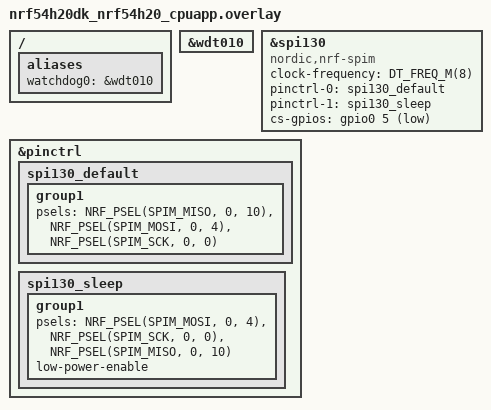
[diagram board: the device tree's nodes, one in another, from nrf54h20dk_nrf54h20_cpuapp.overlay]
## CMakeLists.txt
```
# Copyright (c) 2024 Nordic Semiconductor ASA
# SPDX-License-Identifier: Apache-2.0

cmake_minimum_required(VERSION 3.20.0)
find_package(Zephyr REQUIRED HINTS $ENV{ZEPHYR_BASE})

project(test_power_management)

target_include_directories(app PRIVATE src)

target_sources(app PRIVATE
  src/main.c
  src/watchdog.c
)
```

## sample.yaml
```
sample:
  name: Hello World for multiple board targets using Sysbuild
  description: |
    Hello World application that builds for multiple targets. Both images print
    the board target they were run on.

common:
  sysbuild: true
  harness: console
  harness_config:
    type: multi_line
    regex:
      - "Hello world from .*"

tests:
  sample.sysbuild.hello_world.nrf5340dk_cpuapp_cpunet:
    platform_allow:
      - nrf5340dk/nrf5340/cpuapp
    integration_platforms:
      - nrf5340dk/nrf5340/cpuapp
    extra_args:
      SB_CONF_FILE=sysbuild/nrf5340dk_nrf5340_cpunet.conf

  sample.sysbuild.test_power_management.nrf54h20dk_cpuapp_cpurad:
    platform_allow:
      - nrf54h20dk/nrf54h20/cpuapp
    integration_platforms:
      - nrf54h20dk/nrf54h20/cpuapp
    extra_args:
      SB_CONF_FILE=sysbuild/nrf54h20dk_nrf54h20_cpurad.conf

  sample.sysbuild.hello_world.nrf54h20dk_cpuapp_cpuppr:
    platform_allow:
      - nrf54h20dk/nrf54h20/cpuapp
    integration_platforms:
      - nrf54h20dk/nrf54h20/cpuapp
    extra_args:
      SB_CONF_FILE=sysbuild/nrf54h20dk_nrf54h20_cpuppr.conf
      hello_world_SNIPPET=nordic-ppr

  sample.sysbuild.hello_world.nrf54h20dk_cpuapp_cpuppr_xip:
    platform_allow:
      - nrf54h20dk/nrf54h20/cpuapp
    integration_platforms:
      - nrf54h20dk/nrf54h20/cpuapp
    extra_args:
      SB_CONF_FILE=sysbuild/nrf54h20dk_nrf54h20_cpuppr_xip.conf
      hello_world_SNIPPET=nordic-ppr-xip

  sample.sysbuild.hello_world.nrf54l15dk_nrf54l15_cpuflpr:
    platform_allow:
      - nrf54l15dk/nrf54l15/cpuapp
    integration_platforms:
      - nrf54l15dk/nrf54l15/cpuapp
    extra_args:
      SB_CONF_FILE=sysbuild/nrf54l15dk_nrf54l15_cpuflpr.conf
      hello_world_SNIPPET=nordic-flpr

  sample.sysbuild.hello_world.nrf54h20dk_cpuapp_cpuflpr:
    platform_allow:
      - nrf54h20dk/nrf54h20/cpuapp
    integration_platforms:
      - nrf54h20dk/nrf54h20/cpuapp
    extra_args:
      SB_CONF_FILE=sysbuild/nrf54h20dk_nrf54h20_cpuflpr.conf
      hello_world_SNIPPET=nordic-flpr

  sample.sysbuild.hello_world.nrf54h20dk_cpuapp_cpuflpr_xip:
    platform_allow:
      - nrf54h20dk/nrf54h20/cpuapp
    integration_platforms:
      - nrf54h20dk/nrf54h20/cpuapp
    extra_args:
      SB_CONF_FILE=sysbuild/nrf54h20dk_nrf54h20_cpuflpr_xip.conf
      hello_world_SNIPPET=nordic-flpr-xip
```

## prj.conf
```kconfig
CONFIG_PM=y
CONFIG_PM_DEVICE=y

# Watchdog timer
CONFIG_WATCHDOG=y
CONFIG_TASK_WDT=y
CONFIG_TASK_WDT_HW_FALLBACK=y
CONFIG_TASK_WDT_MIN_TIMEOUT=5000
CONFIG_TASK_WDT_HW_FALLBACK_DELAY=100

CONFIG_GPIO=y

# Shell and dependencies
CONFIG_THREAD_MONITOR=y
CONFIG_THREAD_NAME=y
CONFIG_SHELL=y
CONFIG_SHELL_THREAD_PRIORITY_OVERRIDE=y
CONFIG_SHELL_THREAD_PRIORITY=10
CONFIG_LOG=y
CONFIG_LOG_PROCESS_TRIGGER_THRESHOLD=1
CONFIG_LOG_SPEED=y
CONFIG_LOG_PRINTK=y
CONFIG_LOG_BUFFER_SIZE=4096
CONFIG_LOG_PROCESS_THREAD_CUSTOM_PRIORITY=y
CONFIG_LOG_PROCESS_THREAD_PRIORITY=10

# Threads statistics
CONFIG_THREAD_RUNTIME_STATS=y
CONFIG_SCHED_THREAD_USAGE_ANALYSIS=y

# Test SPI interface for GPIO reuse with interrupts
CONFIG_SPI=y
```

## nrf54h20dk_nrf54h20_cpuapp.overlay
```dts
&wdt010 {
	status = "okay";
};

&spi130 {
	compatible = "nordic,nrf-spim";
	status = "okay";
	clock-frequency = <DT_FREQ_M(8)>;
	pinctrl-0 = <&spi130_default>;
	pinctrl-1 = <&spi130_sleep>;
	pinctrl-names = "default", "sleep";

	cs-gpios = <&gpio0 5 GPIO_ACTIVE_LOW>;
};

&pinctrl {
	spi130_default: spi130_default {
		group1 {
			psels = <NRF_PSEL(SPIM_MISO, 0, 10)>,
				<NRF_PSEL(SPIM_MOSI, 0, 4)>,
				<NRF_PSEL(SPIM_SCK, 0, 0)>;
		};
	};

	spi130_sleep: spi130_sleep {
		group1 {
			psels = <NRF_PSEL(SPIM_MOSI, 0, 4)>,
				<NRF_PSEL(SPIM_SCK, 0, 0)>,
				<NRF_PSEL(SPIM_MISO, 0, 10)>;
			low-power-enable;
		};
		/*group2 {
			psels = <NRF_PSEL_DISCONNECTED(SPIM_MISO)>;
		};*/
	};
};

/ {
	aliases {
		watchdog0 = &wdt010;
	};
};
```

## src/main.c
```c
#include <zephyr/drivers/gpio.h>
#include <zephyr/ipc/ipc_service.h>
#include <zephyr/kernel.h>
#include <zephyr/pm/policy.h>
#include <zephyr/pm/pm.h>
#include <zephyr/sys/printk.h>

#include "watchdog.h"

#define MAX_SUSPENDABLE_THREADS_COUNT 10

static void resume_system(void);

static const struct gpio_dt_spec app_led = GPIO_DT_SPEC_GET(DT_NODELABEL(led0), gpios);
static const struct gpio_dt_spec app_button_suspend = GPIO_DT_SPEC_GET(DT_NODELABEL(button0), gpios);
static const struct gpio_dt_spec app_button_resume = GPIO_DT_SPEC_GET(DT_NODELABEL(button2), gpios);

static struct gpio_callback suspend_app_button_callback_data;
static struct gpio_callback resume_app_button_callback_data;

static bool is_suspended = false;

static size_t suspendable_threads_count;
static k_tid_t suspendable_thread_ids[MAX_SUSPENDABLE_THREADS_COUNT];

static void ipc_endpoint_bound_callback(void *priv)
{
	printk("IPC endpoint successfully bound\n.");
}

static void ipc_endpoint_received_callback(const void *data, size_t len, void *priv)
{
	printk("Received an IPC message\n.");

	if (is_suspended)
		resume_system();
}

static struct ipc_ept_cfg ipc_endpoint_config =
{
	.name = "ept1",
	.cb =
	{
		.bound = ipc_endpoint_bound_callback,
		.received = ipc_endpoint_received_callback
	}
};
static struct ipc_ept ipc_endpoint;
static const struct device *ipc_instance = DEVICE_DT_GET(DT_NODELABEL(ipc0));

static void __attribute__((unused)) burn_cpu(void)
{
	volatile int a = 0, i;

	for (i = 0; i < 50000000; i++)
	{
		a += 1239;
		a *= -7;
		a /= 11;
	}
}

static void thread_background_entry(void *p1, void *p2, void *p3)
{
	unsigned int i = 0;
	int channel;

	ARG_UNUSED(p1);
	ARG_UNUSED(p2);
	ARG_UNUSED(p3);

	channel = task_wdt_add(2000, watchdog_callback, "background");
	if (channel < 0)
	{
		printk("Failed to initialize the watchdog for background thread; err=%d", -channel);
		return;
	}

	printk("Background thread is ready.\n");

	while (1)
	{
		printk("BACKGROUND %u\n", i);
		i++;

		task_wdt_feed(channel);
		k_msleep(1000);
	}
}
// Higher priority thread to be able to interrupt the busy waits in the main thread
K_THREAD_DEFINE(thread_background, 512, thread_background_entry, NULL, NULL, NULL, -1, K_ESSENTIAL, 1);

static void cache_suspendable_thread_callback(const struct k_thread *thread, void *user_data)
{
	k_tid_t thread_id;
	const char *name;
	bool keep_thread = false;

	ARG_UNUSED(user_data);

	// Retrieve the current thread name
	thread_id = (k_tid_t) thread;
	name = k_thread_name_get(thread_id);

	// Do not try to identify the thread if it has no name
	if (name == NULL)
		return;

	// The shell thread is always ready and keeps waking the system, so it needs to be suspended
	if (strcmp(name, "main") == 0)
		keep_thread = true;
	else if (strcmp(name, "shell_uart") == 0)
		keep_thread = true;
	else if (strcmp(name, "logging") == 0)
		keep_thread = true;
	else if (strcmp(name, "thread_background") == 0)
		keep_thread = true;

	if (keep_thread)
	{
		if (suspendable_threads_count >= MAX_SUSPENDABLE_THREADS_COUNT)
		{
			printk("No more room in the suspendable threads array.");
			k_sleep(K_FOREVER);
		}
		suspendable_thread_ids[suspendable_threads_count] = thread_id;
		suspendable_threads_count++;
		printk("Added the thread named \"%s\" to the suspendable list.\n", name);
	}
}

static void cache_suspendable_threads()
{
    suspendable_threads_count = 0;

    k_thread_foreach(cache_suspendable_thread_callback, NULL);

    printk("Cached %zu suspendable threads.\n", suspendable_threads_count);
}

static void suspend_threads()
{
	const char *name;
	k_tid_t thread_id;

	for (size_t i = 0; i < suspendable_threads_count; i++)
	{
		thread_id = suspendable_thread_ids[i];
		k_thread_suspend(thread_id);

		name = k_thread_name_get(thread_id);
		printk("Suspending thread named \"%s\".\n", name);
	}
}

static void resume_threads()
{
	const char *name;
	k_tid_t thread_id;

	for (size_t i = 0; i < suspendable_threads_count; i++)
	{
		thread_id = suspendable_thread_ids[i];
		k_thread_resume(thread_id);

		name = k_thread_name_get(thread_id);
		printk("Resuming thread named \"%s\".\n", name);
	}
}

static void gpio_callback(const struct device *port, struct gpio_callback *cb, gpio_port_pins_t pins)
{
	ARG_UNUSED(port);
	ARG_UNUSED(cb);
	ARG_UNUSED(pins);

	printk("\033[35mGPIO interrupt callback.\033[0m\n");

	if (!is_suspended && (pins & (1 << 8)))
	{
		printk("\033[35mSUSPEND\033[0m\n");
		pm_policy_state_lock_put(PM_STATE_SUSPEND_TO_IDLE, PM_ALL_SUBSTATES); // Allow reaching suspend to idle
		task_wdt_suspend();
		suspend_threads();
		is_suspended = true;
	}
	else if (is_suspended && (pins & (1 << 10)))
	{
		printk("\033[35mRESUME\033[0m\n");
		resume_system();

		// Tell the radio core to wake up (the message content is ignored for now)
		ipc_service_send(&ipc_endpoint, "wake", 5);
	}
}

static void resume_system(void)
{
	task_wdt_resume();
	resume_threads();
	pm_policy_state_lock_get(PM_STATE_SUSPEND_TO_IDLE, PM_ALL_SUBSTATES); // Stay in active mode
	is_suspended = false;
}

void power_notifier_entry(enum pm_state state)
{
	if (state == PM_STATE_SUSPEND_TO_IDLE)
	{
		// Tell that the App core is in suspend to idle mode
		gpio_pin_set_dt(&app_led, 1);
	}
}

void power_notifier_exit(enum pm_state state)
{
	if (state == PM_STATE_SUSPEND_TO_IDLE)
	{
		// Tell that the App core exited the suspend to idle mode
		gpio_pin_set_dt(&app_led, 0);
	}
}

static struct pm_notifier power_notifier =
{
	.state_entry = power_notifier_entry,
	.state_exit = power_notifier_exit
};

int main(void)
{
	int states_count, ret, channel;
	const struct pm_state_info *states;
	unsigned int i = 0;
	uint32_t start_time = 0, current_time;

	/* Set the main thread priority less than the shell and logging threads,
	 * so they continue working while the main thread is using 100% of the remaining resources.
	 */
	k_thread_priority_set(k_current_get(), 12);

	// Force staying in active mode by locking all other states
	pm_policy_state_lock_get(PM_STATE_RUNTIME_IDLE, PM_ALL_SUBSTATES);
	pm_policy_state_lock_get(PM_STATE_SUSPEND_TO_IDLE, PM_ALL_SUBSTATES);
	pm_policy_state_lock_get(PM_STATE_STANDBY, PM_ALL_SUBSTATES);
	pm_policy_state_lock_get(PM_STATE_SUSPEND_TO_RAM, PM_ALL_SUBSTATES);
	pm_policy_state_lock_get(PM_STATE_SUSPEND_TO_DISK, PM_ALL_SUBSTATES);

	cache_suspendable_threads();

	// Callbacks called when the power mode changes
	pm_notifier_register(&power_notifier);

	ret = watchdog_init();
	if (ret < 0)
		return -1;

	printk("Hello world from %s\n", CONFIG_BOARD_TARGET);

	// Retrieving power states
	states_count = pm_state_cpu_get_all(0, &states);
	printk("Power states count : %d.\n", states_count);

	if (!gpio_is_ready_dt(&app_led))
	{
		printk("App LED GPIO is not ready.\n");
		return -1;
	}
	if (!gpio_is_ready_dt(&app_button_resume))
	{
		printk("Suspend App button GPIO is not ready.\n");
		return -1;
	}
	if (!gpio_is_ready_dt(&app_button_suspend))
	{
		printk("Resume App button GPIO is not ready.\n");
		return -1;
	}

	ret = gpio_pin_configure_dt(&app_led, GPIO_OUTPUT_ACTIVE);
	if (ret < 0)
	{
		printk("Failed to configure the App LED GPIO (%d).\n", ret);
		return -1;
	}
	ret = gpio_pin_configure_dt(&app_button_resume, GPIO_INPUT | GPIO_PULL_UP);
	if (ret < 0)
	{
		printk("Failed to configure the suspend App button GPIO (%d).\n", ret);
		return -1;
	}
	ret = gpio_pin_configure_dt(&app_button_suspend, GPIO_INPUT | GPIO_PULL_UP);
	if (ret < 0)
	{
		printk("Failed to configure the resume App button GPIO (%d).\n", ret);
		return -1;
	}

	ret = gpio_pin_interrupt_configure_dt(&app_button_suspend, GPIO_INT_EDGE_FALLING);
	if (ret < 0)
	{
		printk("Failed to configure the suspend App button interrupt (%d).\n", ret);
		return -1;
	}
	ret = gpio_pin_interrupt_configure_dt(&app_button_resume, GPIO_INT_EDGE_FALLING);
	if (ret < 0)
	{
		printk("Failed to configure the resume App button interrupt (%d).\n", ret);
		return -1;
	}

	gpio_init_callback(&suspend_app_button_callback_data, gpio_callback, BIT(app_button_suspend.pin));
	if (gpio_add_callback_dt(&app_button_suspend, &suspend_app_button_callback_data) < 0)
	{
		printk("Failed to add a callback to the suspend App button GPIO.\n");
		return -1;
	}
	gpio_init_callback(&resume_app_button_callback_data, gpio_callback, BIT(app_button_resume.pin));
	if (gpio_add_callback_dt(&app_button_resume, &resume_app_button_callback_data) < 0)
	{
		printk("Failed to add a callback to the resume App button GPIO.\n");
		return -1;
	}

	ret = ipc_service_open_instance(ipc_instance);
	if ((ret != 0) && (ret != -EALREADY))
	{
		printk("Failed to open the inter processor service instance (%d).", ret);
		return ret;
	}

	ret = ipc_service_register_endpoint(ipc_instance, &ipc_endpoint, &ipc_endpoint_config);
	if (ret != 0)
	{
		printk("Failed to register the inter processor service endpoint (%d).", ret);
		return ret;
	}

	// Turn the power mode LED off to tell that the board is in active mode
	gpio_pin_set_dt(&app_led, 0);

	channel = task_wdt_add(2000, watchdog_callback, "main");
	if (channel < 0)
	{
		printk("Failed to initialize the watchdog for background thread; err=%d", -channel);
		return -1;
	}

	while (1)
	{
		printk("MAIN %u\n", i);
		i++;

		/* Wait 1 second without sleeping, so we do not enter any power management state and
		 * this makes the core consume as much energy as possible.
		 */
		do
		{
			current_time = k_uptime_get_32();
		} while ((current_time - start_time) < 1000);
		start_time = current_time;

		task_wdt_feed(channel);
	}

	return 0;
}
```

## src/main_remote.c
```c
#include <zephyr/drivers/gpio.h>
#include <zephyr/ipc/ipc_service.h>
#include <zephyr/kernel.h>
#include <zephyr/pm/policy.h>
#include <zephyr/pm/pm.h>
#include <zephyr/sys/printk.h>

#include "watchdog.h"

#define MAX_SUSPENDABLE_THREADS_COUNT 10

static void resume_system(void);

static const struct gpio_dt_spec radio_led = GPIO_DT_SPEC_GET(DT_NODELABEL(radio_led), gpios);
static const struct gpio_dt_spec radio_button_suspend = GPIO_DT_SPEC_GET(DT_NODELABEL(radio_button_suspend), gpios);
static const struct gpio_dt_spec radio_button_resume = GPIO_DT_SPEC_GET(DT_NODELABEL(radio_button_resume), gpios);

static struct gpio_callback suspend_radio_button_callback_data;
static struct gpio_callback resume_radio_button_callback_data;

static bool is_suspended = false;
static volatile bool enable_notifier_message = false;

static size_t suspendable_threads_count;
static k_tid_t suspendable_thread_ids[MAX_SUSPENDABLE_THREADS_COUNT];

static struct pm_policy_latency_request latency_request;

static void ipc_endpoint_bound_callback(void *priv)
{
	printk("IPC endpoint successfully bound.\n");
}

static void ipc_endpoint_received_callback(const void *data, size_t len, void *priv)
{
	printk("Received an IPC message\n.");

	if (is_suspended)
		resume_system();
}

static struct ipc_ept_cfg ipc_endpoint_config =
{
	.name = "ept1",
	.cb =
	{
		.bound = ipc_endpoint_bound_callback,
		.received = ipc_endpoint_received_callback
	}
};
static struct ipc_ept ipc_endpoint;
static const struct device *ipc_instance = DEVICE_DT_GET(DT_NODELABEL(ipc0));

static void __attribute__((unused)) burn_cpu(void)
{
	volatile int a = 0, i;

	for (i = 0; i < 50000000; i++)
	{
		a += 1239;
		a *= -7;
		a /= 11;
	}
}

static void thread_background_entry(void *p1, void *p2, void *p3)
{
	unsigned int i = 0;
	int channel;

	ARG_UNUSED(p1);
	ARG_UNUSED(p2);
	ARG_UNUSED(p3);

	channel = task_wdt_add(2000, watchdog_callback, "background");
	if (channel < 0)
	{
		printk("Failed to initialize the watchdog for background thread; err=%d", -channel);
		return;
	}

	printk("Background thread is ready.\n");

	while (1)
	{
		printk("BACKGROUND %u\n", i);
		i++;

		task_wdt_feed(channel);
		k_msleep(1000);
	}
}
// Higher priority thread to be able to interrupt the busy wait in the main thread
K_THREAD_DEFINE(thread_background, 512, thread_background_entry, NULL, NULL, NULL, -1, K_ESSENTIAL, 1);

static void thread_semaphore_entry(void *p1, void *p2, void *p3)
{
	unsigned int i = 0;
	int channel, ret;
	struct k_sem semaphore;

	ARG_UNUSED(p1);
	ARG_UNUSED(p2);
	ARG_UNUSED(p3);

	channel = task_wdt_add(2000, watchdog_callback, "semaphore");
	if (channel < 0)
	{
		printk("Failed to initialize the watchdog for semaphore thread (%d)", -channel);
		return;
	}

	ret = k_sem_init(&semaphore, 0, 1);
	if (ret < 0)
	{
		printk("Failed to initialize the semaphore (%d).\n", ret);
		return;
	}

	printk("Semaphore thread is ready.\n");

	while (1)
	{
		printk("SEMAPHORE %u\n", i);
		i++;

		task_wdt_feed(channel);
		ret = k_sem_take(&semaphore, K_MSEC(1000));
		if (ret != -EAGAIN)
		{
			printk("Failed to take the semaphore (%d).\n", ret);
			return;
		}
	}
}
// Higher priority thread to be able to interrupt the busy wait in the main thread
K_THREAD_DEFINE(thread_semaphore, 512, thread_semaphore_entry, NULL, NULL, NULL, -1, K_ESSENTIAL, 1);

static void notifier_exit(enum pm_state state)
{
	if (enable_notifier_message)
		printk("Resuming...\n");
}
static struct pm_notifier notifier = { .state_exit = notifier_exit };

static void cache_suspendable_thread_callback(const struct k_thread *thread, void *user_data)
{
	k_tid_t thread_id;
	const char *name;
	bool keep_thread = false;

	ARG_UNUSED(user_data);

	// Retrieve the current thread name
	thread_id = (k_tid_t) thread;
	name = k_thread_name_get(thread_id);

	// Do not try to identify the thread if it has no name
	if (name == NULL)
		return;

	// The shell thread is always ready and keeps waking the system, so it needs to be suspended
	if (strcmp(name, "main") == 0)
		keep_thread = true;
	else if (strcmp(name, "shell_uart") == 0)
		keep_thread = true;
	else if (strcmp(name, "logging") == 0)
		keep_thread = true;
	else if (strcmp(name, "thread_background") == 0)
		keep_thread = true;
	else if (strcmp(name, "thread_semaphore") == 0)
		keep_thread = true;

	if (keep_thread)
	{
		if (suspendable_threads_count >= MAX_SUSPENDABLE_THREADS_COUNT)
		{
			printk("No more room in the suspendable threads array.");
			k_sleep(K_FOREVER);
		}
		suspendable_thread_ids[suspendable_threads_count] = thread_id;
		suspendable_threads_count++;
		printk("Added the thread named \"%s\" to the suspendable list.\n", name);
	}
}

static void cache_suspendable_threads()
{
    suspendable_threads_count = 0;

    k_thread_foreach(cache_suspendable_thread_callback, NULL);

    printk("Cached %zu suspendable threads.\n", suspendable_threads_count);
}

static void suspend_threads()
{
	const char *name;
	k_tid_t thread_id;

	for (size_t i = 0; i < suspendable_threads_count; i++)
	{
		thread_id = suspendable_thread_ids[i];
		k_thread_suspend(thread_id);

		name = k_thread_name_get(thread_id);
		printk("Suspending thread named \"%s\".\n", name);
	}
}

static void resume_threads()
{
	const char *name;
	k_tid_t thread_id;

	for (size_t i = 0; i < suspendable_threads_count; i++)
	{
		thread_id = suspendable_thread_ids[i];
		k_thread_resume(thread_id);

		name = k_thread_name_get(thread_id);
		printk("Resuming thread named \"%s\".\n", name);
	}
}

static void gpio_callback(const struct device *port, struct gpio_callback *cb, gpio_port_pins_t pins)
{
	ARG_UNUSED(port);
	ARG_UNUSED(cb);
	ARG_UNUSED(pins);

	printk("\033[35mGPIO interrupt callback.\033[0m\n");

	if (!is_suspended && (pins & (1 << 2)))
	{
		enable_notifier_message = true;
		printk("\033[35mSUSPEND\033[0m\n");
		gpio_pin_set_dt(&radio_led, 0); // Make sure the LED is off, so it does not impact power measurements
		pm_policy_latency_request_remove(&latency_request); // Allow reaching suspend to idle
		task_wdt_suspend();
		suspend_threads();
		is_suspended = true;
	}
	else if (is_suspended && (pins & (1 << 3)))
	{
		printk("\033[35mRESUME\033[0m\n");
		resume_system();

		// Tell the app core to wake up (the message content is ignored for now)
		ipc_service_send(&ipc_endpoint, "wakeFromRad", 12);
	}
}

static void resume_system(void)
{
	task_wdt_resume();
	resume_threads();
	pm_policy_latency_request_add(&latency_request, 1); // Stay in active mode
	enable_notifier_message = false;
	is_suspended = false;
}

int main(void)
{
	int states_count, ret;
	const struct pm_state_info *states;
	unsigned int i = 0;
	uint32_t start_time = 0, current_time;

	/* Set the main thread priority less than the shell and logging threads,
	 * so they continue working while the main thread is using 100% of the remaining resources.
	 */
	k_thread_priority_set(k_current_get(), 12);

	cache_suspendable_threads();

	ret = watchdog_init();
	if (ret < 0)
		return -1;

	pm_notifier_register(&notifier);

	printk("Hello world from %s\n", CONFIG_BOARD_TARGET);

	// Retrieving power states
	states_count = pm_state_cpu_get_all(0, &states);
	printk("Power states count : %d.\n", states_count);

	if (!gpio_is_ready_dt(&radio_led))
	{
		printk("Radio LED GPIO is not ready.\n");
		return -1;
	}
	if (!gpio_is_ready_dt(&radio_button_resume))
	{
		printk("Suspend Radio button GPIO is not ready.\n");
		return -1;
	}
	if (!gpio_is_ready_dt(&radio_button_suspend))
	{
		printk("Resume Radio button GPIO is not ready.\n");
		return -1;
	}

	if (gpio_pin_configure_dt(&radio_led, GPIO_OUTPUT_ACTIVE) < 0)
	{
		printk("Failed to configure the Radio LED GPIO.\n");
		return -1;
	}
	ret = gpio_pin_configure_dt(&radio_button_resume, GPIO_INPUT | GPIO_PULL_UP);
	if (ret < 0)
	{
		printk("Failed to configure the suspend Radio button GPIO (%d).\n", ret);
		return -1;
	}
	ret = gpio_pin_configure_dt(&radio_button_suspend, GPIO_INPUT | GPIO_PULL_UP);
	if (ret < 0)
	{
		printk("Failed to configure the resume Radio button GPIO (%d).\n", ret);
		return -1;
	}

	ret = gpio_pin_interrupt_configure_dt(&radio_button_suspend, GPIO_INT_EDGE_FALLING);
	if (ret < 0)
	{
		printk("Failed to configure the suspend Radio button interrupt (%d).\n", ret);
		return -1;
	}
	ret = gpio_pin_interrupt_configure_dt(&radio_button_resume, GPIO_INT_EDGE_FALLING);
	if (ret < 0)
	{
		printk("Failed to configure the resume Radio button interrupt (%d).\n", ret);
		return -1;
	}

	gpio_init_callback(&suspend_radio_button_callback_data, gpio_callback, BIT(radio_button_suspend.pin));
	if (gpio_add_callback_dt(&radio_button_suspend, &suspend_radio_button_callback_data) < 0)
	{
		printk("Failed to add a callback to the suspend Radio button GPIO.\n");
		return -1;
	}
	gpio_init_callback(&resume_radio_button_callback_data, gpio_callback, BIT(radio_button_resume.pin));
	if (gpio_add_callback_dt(&radio_button_resume, &resume_radio_button_callback_data) < 0)
	{
		printk("Failed to add a callback to the resume Radio button GPIO.\n");
		return -1;
	}

	ret = ipc_service_open_instance(ipc_instance);
	if ((ret != 0) && (ret != -EALREADY))
	{
		printk("Failed to open the inter processor service instance (%d).", ret);
		return ret;
	}

	ret = ipc_service_register_endpoint(ipc_instance, &ipc_endpoint, &ipc_endpoint_config);
	if (ret != 0)
	{
		printk("Failed to register the inter processor service endpoint (%d).", ret);
		return ret;
	}

	// Force staying in active mode by specifying a latency that can't be reached by any state
	pm_policy_latency_request_add(&latency_request, 1);

	while (1)
	{
		printk("MAIN %u\n", i);
		i++;

		/* Wait 1 second without sleeping, so we do not enter any power management state and
		 * this makes the core consume as much energy as possible.
		 */
		do
		{
			current_time = k_uptime_get_32();
		} while ((current_time - start_time) < 1000);
		start_time = current_time;

		gpio_pin_toggle_dt(&radio_led);
	}

	return 0;
}
```

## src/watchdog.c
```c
#include <zephyr/drivers/watchdog.h>
#include <zephyr/sys/printk.h>

#include "watchdog.h"

#define WATCHDOG_NAME watchdog0

int watchdog_init(void)
{
	const struct device *watchdog_device;
	int ret;

	watchdog_device = DEVICE_DT_GET_OR_NULL(DT_ALIAS(WATCHDOG_NAME));
	if (!watchdog_device) {
		printk("Error: failed to get the watchdog device from the device tree.\n");
		return -EINVAL;
	}

	if (!device_is_ready(watchdog_device)) {
		printk("Error: the hardware watchdog device is not ready.\n");
		return -EBUSY;
	}

	ret = task_wdt_init(watchdog_device);
	if (ret != 0) {
		printk("Error: failed to initialize the task watchdog (%d)\n.", ret);
		return ret;
	}

	return 0;
}

void watchdog_callback(int channel_id, void *user_data)
{
	char *cpu_name;
#ifdef NRF_RADIOCORE
	cpu_name = "Radio";
#else
	cpu_name = "App";
#endif

	printk("Task watchdog fired for channel %d on %s core !\n", channel_id, cpu_name);

	// Wait for the hardware watchdog to reset the SoC
	while (1);
}
```

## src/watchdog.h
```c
#ifndef H_WATCHDOG_H
#define H_WATCHDOG_H

// Make the task watchdog API available to the includers of this file
#include <zephyr/task_wdt/task_wdt.h>

int watchdog_init(void);

void watchdog_callback(int channel_id, void *user_data);

#endif
```
